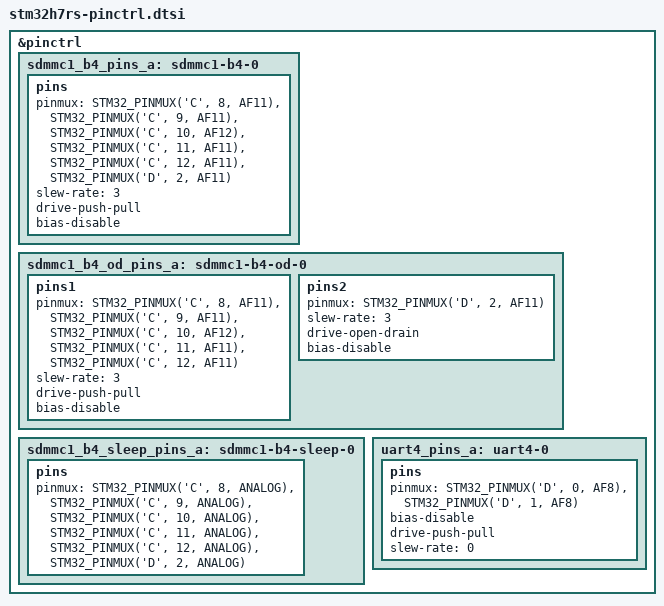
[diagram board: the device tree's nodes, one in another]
// SPDX-License-Identifier: (GPL-2.0-only OR BSD-2-Clause)
/*
 * Copyright (C) 2026 Liu Changjie <liucj1228@outlook.com>
 */

#include <dt-bindings/pinctrl/stm32-pinfunc.h>

&pinctrl {
	sdmmc1_b4_pins_a: sdmmc1-b4-0 {
		pins {
			pinmux = <STM32_PINMUX('C', 8, AF11)>, /* SDMMC1_D0 */
				 <STM32_PINMUX('C', 9, AF11)>, /* SDMMC1_D1 */
				 <STM32_PINMUX('C', 10, AF12)>, /* SDMMC1_D2 */
				 <STM32_PINMUX('C', 11, AF11)>, /* SDMMC1_D3 */
				 <STM32_PINMUX('C', 12, AF11)>, /* SDMMC1_CK */
				 <STM32_PINMUX('D', 2, AF11)>; /* SDMMC1_CMD */
			slew-rate = <3>;
			drive-push-pull;
			bias-disable;
		};
	};

	sdmmc1_b4_od_pins_a: sdmmc1-b4-od-0 {
		pins1 {
			pinmux = <STM32_PINMUX('C', 8, AF11)>, /* SDMMC1_D0 */
				 <STM32_PINMUX('C', 9, AF11)>, /* SDMMC1_D1 */
				 <STM32_PINMUX('C', 10, AF12)>, /* SDMMC1_D2 */
				 <STM32_PINMUX('C', 11, AF11)>, /* SDMMC1_D3 */
				 <STM32_PINMUX('C', 12, AF11)>; /* SDMMC1_CK */
			slew-rate = <3>;
			drive-push-pull;
			bias-disable;
		};

		pins2 {
			pinmux = <STM32_PINMUX('D', 2, AF11)>; /* SDMMC1_CMD */
			slew-rate = <3>;
			drive-open-drain;
			bias-disable;
		};
	};

	sdmmc1_b4_sleep_pins_a: sdmmc1-b4-sleep-0 {
		pins {
			pinmux = <STM32_PINMUX('C', 8, ANALOG)>, /* SDMMC1_D0 */
				 <STM32_PINMUX('C', 9, ANALOG)>, /* SDMMC1_D1 */
				 <STM32_PINMUX('C', 10, ANALOG)>, /* SDMMC1_D2 */
				 <STM32_PINMUX('C', 11, ANALOG)>, /* SDMMC1_D3 */
				 <STM32_PINMUX('C', 12, ANALOG)>, /* SDMMC1_CK */
				 <STM32_PINMUX('D', 2, ANALOG)>; /* SDMMC1_CMD */
		};
	};

	uart4_pins_a: uart4-0 {
		pins {
			pinmux = <STM32_PINMUX('D', 0, AF8)>, /* UART4_RX */
				 <STM32_PINMUX('D', 1, AF8)>; /* UART4_TX */
			bias-disable;
			drive-push-pull;
			slew-rate = <0>;
		};
	};
};
